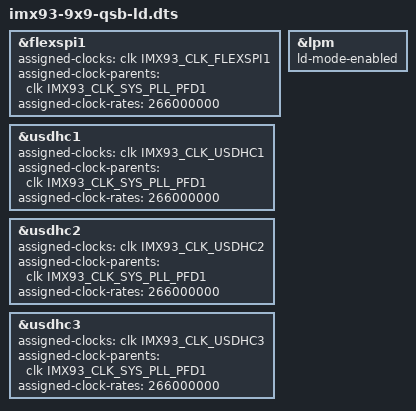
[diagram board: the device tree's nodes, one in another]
// SPDX-License-Identifier: (GPL-2.0+ OR MIT)
/*
 * Copyright 2023 NXP
 */

#include "imx93-9x9-qsb.dts"

&flexspi1 {
	assigned-clocks = <&clk IMX93_CLK_FLEXSPI1>;
	assigned-clock-parents = <&clk IMX93_CLK_SYS_PLL_PFD1>;
	assigned-clock-rates = <266000000>;
};

&lpm {
	ld-mode-enabled;
};

&usdhc1 {
	assigned-clocks = <&clk IMX93_CLK_USDHC1>;
	assigned-clock-parents = <&clk IMX93_CLK_SYS_PLL_PFD1>;
	assigned-clock-rates = <266000000>;
};

&usdhc2 {
	assigned-clocks = <&clk IMX93_CLK_USDHC2>;
	assigned-clock-parents = <&clk IMX93_CLK_SYS_PLL_PFD1>;
	assigned-clock-rates = <266000000>;
};

&usdhc3 {
	assigned-clocks = <&clk IMX93_CLK_USDHC3>;
	assigned-clock-parents = <&clk IMX93_CLK_SYS_PLL_PFD1>;
	assigned-clock-rates = <266000000>;
};
